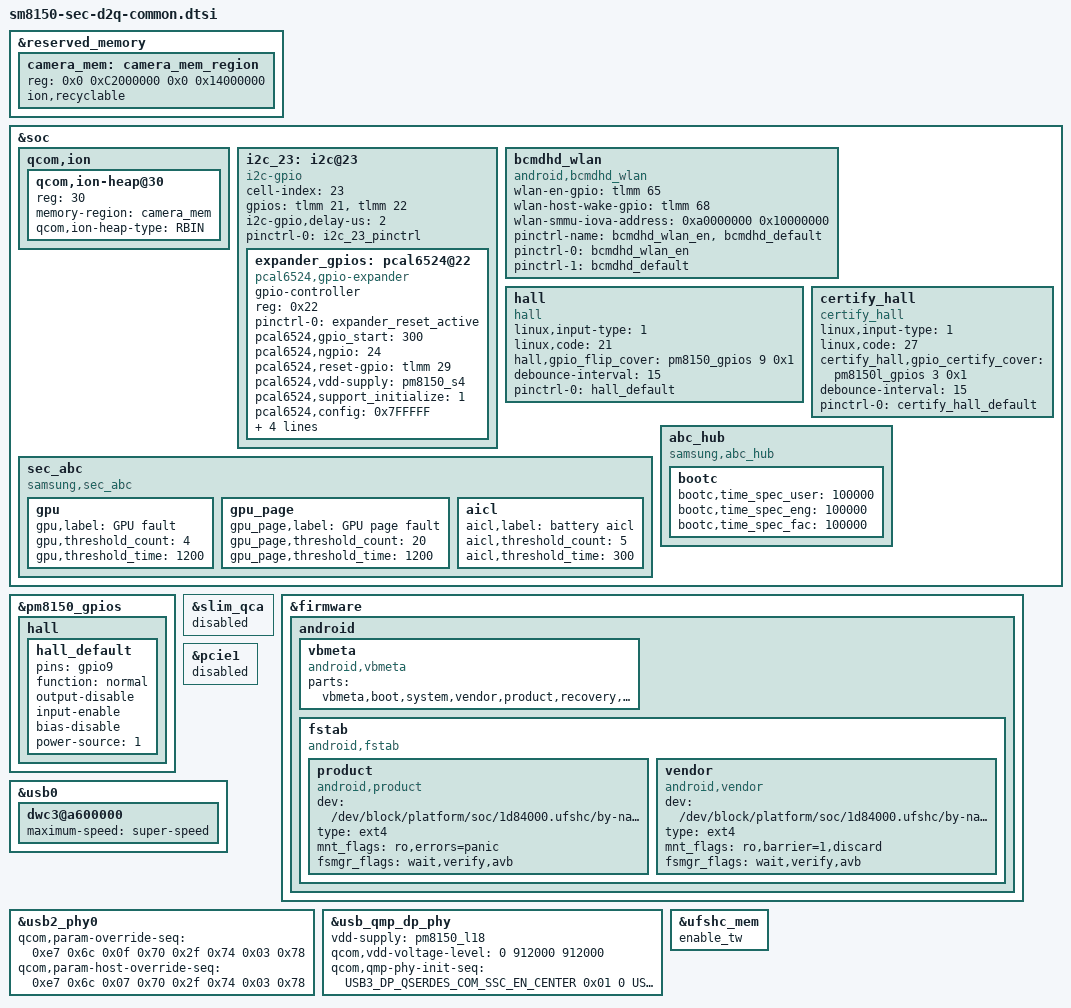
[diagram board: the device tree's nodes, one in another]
/* Copyright (c) 2016-2017, The Linux Foundation. All rights reserved.
 *
 * This program is free software; you can redistribute it and/or modify
 * it under the terms of the GNU General Public License version 2 and
 * only version 2 as published by the Free Software Foundation.
 *
 * This program is distributed in the hope that it will be useful,
 * but WITHOUT ANY WARRANTY; without even the implied warranty of
 * MERCHANTABILITY or FITNESS FOR A PARTICULAR PURPOSE.  See the
 * GNU General Public License for more details.
 */

#include "sm8150-sec-davinciq-audio.dtsi"
#include "sm8150-sec-d2xq-mst.dtsi"
#include <dt-bindings/phy/qcom,sm8150-qmp-usb3.h>
#include "sm8150-sec-d2q-input-common.dtsi"

&reserved_memory {
	camera_mem: camera_mem_region {
		reg = <0x0 0xC2000000 0x0 0x14000000>;
		ion,recyclable;
	};
};

&soc {
	qcom,ion {
		qcom,ion-heap@30 { /* CAMERA HEAP  */
			reg = <30>;
			memory-region = <&camera_mem>;
			qcom,ion-heap-type = "RBIN";
		};
	};
};

&pm8150_gpios {
	hall {
		hall_default: hall_default {
			pins = "gpio9";
			function = "normal";
			output-disable;
			input-enable;
			bias-disable;
			power-source = <1>;
		};
	};
};

&soc {
	i2c_23: i2c@23 {
		status = "ok";

		cell-index = <23>;
		compatible = "i2c-gpio";
		gpios = <&tlmm 21 0	/* EXPANDER_I2C_SDA_1P8 */
			 &tlmm 22 0	/* EXPANDER_I2C_SCL_1P8 */
		>;
		i2c-gpio,delay-us = <2>;
		#address-cells = <1>;
		#size-cells = <0>;

		pinctrl-names = "default";
		pinctrl-0 = <&i2c_23_pinctrl>;

		expander_gpios: pcal6524@22 {
			compatible = "pcal6524,gpio-expander";
			gpio-controller;
			#gpio-cells = <2>;
			reg = <0x22>;
			pinctrl-names = "expander_reset_setting";
			pinctrl-0 = <&expander_reset_active>;
			pcal6524,gpio_start = <300>;
			pcal6524,ngpio = <24>;
			pcal6524,reset-gpio = <&tlmm 29 0>;
			pcal6524,vdd-supply = <&pm8150_s4>;
			pcal6524,support_initialize = <1>;
			/* config, 24 ~ 0, 1bit configure[1:input, 0:output]*/
			pcal6524,config = <0x7FFFFF>;    /* P2[01111111] P1[11111111] P0[11111111] */
			/* data_out, 24 ~ 0, 1bit configure[1:high, 0:low]*/
			pcal6524,data_out = <0x000000>;  /* P2[00000000] P1[00000000] P0[00000000] */
			/* pull_reg, 8 ~ 0, 2bit configure[00:no_pull, 01:pull_down, 10:pull_up, 11:not used] */
			pcal6524,pull_reg_p0 = <0x0000>; /* 00 00 00 00 / 00 00 00 00 */
			pcal6524,pull_reg_p1 = <0x0000>; /* 00 00 00 00 / 00 00 00 00 */
			pcal6524,pull_reg_p2 = <0x0000>; /* 00 00 00 00 / 00 00 00 00 */
		};
	};

       bcmdhd_wlan {
		 compatible = "android,bcmdhd_wlan";
		 wlan-en-gpio = <&tlmm 65 0>;
		 wlan-host-wake-gpio = <&tlmm 68 0>;
		 wlan-smmu-iova-address = <0xa0000000 0x10000000>;
		 pinctrl-name = "bcmdhd_wlan_en","bcmdhd_default";
		 pinctrl-0 = <&bcmdhd_wlan_en>;
		 pinctrl-1 = <&bcmdhd_default>;
		 status = "ok";
	};

        hall {
                status = "okay";
                compatible = "hall";
                linux,input-type = <1>;
                linux,code = <21>;
                hall,gpio_flip_cover = <&pm8150_gpios 9 0x1>;
                debounce-interval = <15>;
		pinctrl-names = "default";
	        pinctrl-0 = <&hall_default>;
        };

        certify_hall {
                compatible = "certify_hall";
                linux,input-type = <1>;
                linux,code = <27>;
                certify_hall,gpio_certify_cover = <&pm8150l_gpios 3 0x1>;
                debounce-interval = <15>;
		pinctrl-names = "default";
	        pinctrl-0 = <&certify_hall_default>;
        };


	sec_abc {
		compatible = "samsung,sec_abc";
		status = "okay";

		gpu {
			gpu,label="GPU fault";
			gpu,threshold_count=<4>;
			gpu,threshold_time=<1200>;
		};
		gpu_page {
			gpu_page,label="GPU page fault";
			gpu_page,threshold_count=<20>;
			gpu_page,threshold_time=<1200>;
		};
		aicl {
			aicl,label="battery aicl";
			aicl,threshold_count=<5>;
			aicl,threshold_time=<300>;
		};
	};

	abc_hub {
		compatible = "samsung,abc_hub";
		status = "okay";

		bootc {
			bootc,time_spec_user = <100000>; /* user binary user build */
			bootc,time_spec_eng = <100000>; /* user binary eng build */
			bootc,time_spec_fac = <100000>; /* factory binary */
		};

	};
};

&slim_qca {
	status = "disabled";
};

&firmware {
	android {
		vbmeta {
			compatible = "android,vbmeta";
			parts = "vbmeta,boot,system,vendor,product,recovery,dtbo,abl,xbl,tz,hyp";
		};
		fstab {
            compatible = "android,fstab";
			product {
				compatible = "android,product";
				/* dev = "/dev/block/bootdevice/by-name/product"; */
				dev = "/dev/block/platform/soc/1d84000.ufshc/by-name/product";
				type = "ext4";
				mnt_flags = "ro,errors=panic";
				fsmgr_flags = "wait,verify,avb";
			};
			vendor {
				compatible = "android,vendor";
				/*dev = "/dev/block/bootdevice/by-name/vendor";*/
				dev = "/dev/block/platform/soc/1d84000.ufshc/by-name/vendor";
				type = "ext4";
				mnt_flags = "ro,barrier=1,discard";
				fsmgr_flags = "wait,verify,avb";
			};
		};
	};
};

&pcie1{
	status = "disabled";
};

&usb0 {
	dwc3@a600000 {
		maximum-speed = "super-speed";
	};
};

&usb2_phy0 {
	qcom,param-override-seq =
		<0xe7 0x6c
		 0x0f 0x70
		 0x2f 0x74
		 0x03 0x78>;
	qcom,param-host-override-seq =
		<0xe7 0x6c
		 0x07 0x70
		 0x2f 0x74
		 0x03 0x78>;
};

&usb_qmp_dp_phy {
	vdd-supply = <&pm8150_l18>;
	qcom,vdd-voltage-level = <0 912000 912000>;
	qcom,qmp-phy-init-seq =
	    <USB3_DP_QSERDES_COM_SSC_EN_CENTER 0x01 0
	     USB3_DP_QSERDES_COM_SSC_PER1 0x31 0
	     USB3_DP_QSERDES_COM_SSC_PER2 0x01 0
	     USB3_DP_QSERDES_COM_SSC_STEP_SIZE1_MODE0 0xde 0
	     USB3_DP_QSERDES_COM_SSC_STEP_SIZE2_MODE0 0x07 0
	     USB3_DP_QSERDES_COM_SSC_STEP_SIZE1_MODE1 0xde 0
	     USB3_DP_QSERDES_COM_SSC_STEP_SIZE2_MODE1 0x07 0
	     USB3_DP_QSERDES_COM_SYSCLK_BUF_ENABLE 0x0a 0
	     USB3_DP_QSERDES_COM_CP_CTRL_MODE0 0x06 0
	     USB3_DP_QSERDES_COM_CP_CTRL_MODE1 0x06 0
	     USB3_DP_QSERDES_COM_PLL_RCTRL_MODE0 0x16 0
	     USB3_DP_QSERDES_COM_PLL_RCTRL_MODE1 0x16 0
	     USB3_DP_QSERDES_COM_PLL_CCTRL_MODE0 0x36 0
	     USB3_DP_QSERDES_COM_PLL_CCTRL_MODE1 0x36 0
	     USB3_DP_QSERDES_COM_SYSCLK_EN_SEL 0x1a 0
	     USB3_DP_QSERDES_COM_LOCK_CMP_EN 0x04 0
	     USB3_DP_QSERDES_COM_LOCK_CMP1_MODE0 0x14 0
	     USB3_DP_QSERDES_COM_LOCK_CMP2_MODE0 0x34 0
	     USB3_DP_QSERDES_COM_LOCK_CMP1_MODE1 0x34 0
	     USB3_DP_QSERDES_COM_LOCK_CMP2_MODE1 0x82 0
	     USB3_DP_QSERDES_COM_DEC_START_MODE0 0x82 0
	     USB3_DP_QSERDES_COM_DEC_START_MODE1 0x82 0
	     USB3_DP_QSERDES_COM_DIV_FRAC_START1_MODE0 0xab 0
	     USB3_DP_QSERDES_COM_DIV_FRAC_START2_MODE0 0xea 0
	     USB3_DP_QSERDES_COM_DIV_FRAC_START3_MODE0 0x02 0
	     USB3_DP_QSERDES_COM_DIV_FRAC_START1_MODE1 0xab 0
	     USB3_DP_QSERDES_COM_DIV_FRAC_START2_MODE1 0xea 0
	     USB3_DP_QSERDES_COM_DIV_FRAC_START3_MODE1 0x02 0
	     USB3_DP_QSERDES_COM_VCO_TUNE1_MODE0 0x24 0
	     USB3_DP_QSERDES_COM_VCO_TUNE1_MODE1 0x24 0
	     USB3_DP_QSERDES_COM_VCO_TUNE2_MODE1 0x02 0
	     USB3_DP_QSERDES_COM_HSCLK_SEL 0x01 0
	     USB3_DP_QSERDES_COM_CORECLK_DIV_MODE1 0x08 0
	     USB3_DP_QSERDES_COM_SVS_MODE_CLK_SEL 0x2 0
	     USB3_DP_QSERDES_COM_BIN_VCOCAL_CMP_CODE1_MODE0 0xca 0
	     USB3_DP_QSERDES_COM_BIN_VCOCAL_CMP_CODE2_MODE0 0x1e 0
	     USB3_DP_QSERDES_COM_BIN_VCOCAL_CMP_CODE1_MODE1 0xca 0
	     USB3_DP_QSERDES_COM_BIN_VCOCAL_CMP_CODE2_MODE1 0x1e 0
	     USB3_DP_QSERDES_COM_BIN_VCOCAL_HSCLK_SEL 0x11 0
	     USB3_DP_QSERDES_COM_VCO_TUNE_MAP 0x02 0
	     USB3_DP_QSERDES_COM_CMN_IPTRIM 0x20 0
	     USB3_DP_QSERDES_TXA_LANE_MODE_1 0xd5 0
	     USB3_DP_QSERDES_TXA_RCV_DETECT_LVL_2 0x12 0
	     USB3_DP_QSERDES_TXA_RES_CODE_LANE_TX 0x00 0
	     USB3_DP_QSERDES_TXA_RES_CODE_LANE_RX 0x00 0
	     USB3_DP_QSERDES_TXA_RES_CODE_LANE_OFFSET_TX 0x16 0
	     USB3_DP_QSERDES_TXA_RES_CODE_LANE_OFFSET_RX 0x05 0
	     USB3_DP_QSERDES_TXA_PI_QEC_CTRL 0x20 0
	     USB3_DP_QSERDES_TXA_TX_DRV_LVL 0x3a 0
	     USB3_DP_QSERDES_RXA_UCDR_SO_GAIN 0x04 0
	     USB3_DP_QSERDES_RXA_UCDR_FASTLOCK_FO_GAIN 0x2f 0
	     USB3_DP_QSERDES_RXA_UCDR_SO_SATURATION_AND_ENABLE 0x7f 0
	     USB3_DP_QSERDES_RXA_UCDR_FASTLOCK_COUNT_LOW 0xff 0
	     USB3_DP_QSERDES_RXA_UCDR_FASTLOCK_COUNT_HIGH 0x0f 0
	     USB3_DP_QSERDES_RXA_UCDR_PI_CONTROLS 0x99 0
	     USB3_DP_QSERDES_RXA_UCDR_SB2_THRESH1 0x04 0
	     USB3_DP_QSERDES_RXA_UCDR_SB2_THRESH2 0x08 0
	     USB3_DP_QSERDES_RXA_UCDR_SB2_GAIN1 0x05 0
	     USB3_DP_QSERDES_RXA_UCDR_SB2_GAIN2 0x05 0
	     USB3_DP_QSERDES_RXA_AUX_DATA_TCOARSE_TFINE 0xa0 0
	     USB3_DP_QSERDES_RXA_VGA_CAL_CNTRL1 0x54 0
	     USB3_DP_QSERDES_RXA_VGA_CAL_CNTRL2 0x0e 0
	     USB3_DP_QSERDES_RXA_GM_CAL 0x1f 0
	     USB3_DP_QSERDES_RXA_RX_EQU_ADAPTOR_CNTRL2 0x0f 0
	     USB3_DP_QSERDES_RXA_RX_EQU_ADAPTOR_CNTRL3 0x4a 0
	     USB3_DP_QSERDES_RXA_RX_EQU_ADAPTOR_CNTRL4 0x0a 0
	     USB3_DP_QSERDES_RXA_RX_IDAC_TSETTLE_LOW 0xc0 0
	     USB3_DP_QSERDES_RXA_RX_IDAC_TSETTLE_HIGH 0x00 0
	     USB3_DP_QSERDES_RXA_RX_EQ_OFFSET_ADAPTOR_CNTRL1 0x77 0
	     USB3_DP_QSERDES_RXA_RX_OFFSET_ADAPTOR_CNTRL2 0x80 0
	     USB3_DP_QSERDES_RXA_SIGDET_CNTRL 0x04 0
	     USB3_DP_QSERDES_RXA_SIGDET_DEGLITCH_CNTRL 0x0e 0
	     USB3_DP_QSERDES_RXA_RX_MODE_00_LOW 0xbf 0
	     USB3_DP_QSERDES_RXA_RX_MODE_00_HIGH 0xbf 0
	     USB3_DP_QSERDES_RXA_RX_MODE_00_HIGH2 0x3f 0
	     USB3_DP_QSERDES_RXA_RX_MODE_00_HIGH3 0x7f 0
	     USB3_DP_QSERDES_RXA_RX_MODE_00_HIGH4 0x94 0
	     USB3_DP_QSERDES_RXA_RX_MODE_01_LOW 0xdc 0
	     USB3_DP_QSERDES_RXA_RX_MODE_01_HIGH 0xdc 0
	     USB3_DP_QSERDES_RXA_RX_MODE_01_HIGH2 0x5c 0
	     USB3_DP_QSERDES_RXA_RX_MODE_01_HIGH3 0x0b 0
	     USB3_DP_QSERDES_RXA_RX_MODE_01_HIGH4 0xb6 0
	     USB3_DP_QSERDES_RXA_DFE_EN_TIMER 0x04 0
	     USB3_DP_QSERDES_RXA_DFE_CTLE_POST_CAL_OFFSET 0x38 0
	     USB3_DP_QSERDES_RXA_DCC_CTRL1 0xc 0
	     USB3_DP_QSERDES_RXA_VTH_CODE 0x10 0
	     USB3_DP_QSERDES_TXB_LANE_MODE_1 0xd5 0
	     USB3_DP_QSERDES_TXB_RCV_DETECT_LVL_2 0x12 0
	     USB3_DP_QSERDES_TXB_RES_CODE_LANE_TX 0x00 0
	     USB3_DP_QSERDES_TXB_RES_CODE_LANE_RX 0x00 0
	     USB3_DP_QSERDES_TXB_RES_CODE_LANE_OFFSET_TX 0x16 0
	     USB3_DP_QSERDES_TXB_RES_CODE_LANE_OFFSET_RX 0x05 0
	     USB3_DP_QSERDES_TXB_PI_QEC_CTRL 0x20 0
	     USB3_DP_QSERDES_TXB_TX_DRV_LVL 0x3a 0
	     USB3_DP_QSERDES_RXB_UCDR_SO_GAIN 0x04 0
	     USB3_DP_QSERDES_RXB_UCDR_FASTLOCK_FO_GAIN 0x2f 0
	     USB3_DP_QSERDES_RXB_UCDR_SO_SATURATION_AND_ENABLE 0x7f 0
	     USB3_DP_QSERDES_RXB_UCDR_FASTLOCK_COUNT_LOW 0xff 0
	     USB3_DP_QSERDES_RXB_UCDR_FASTLOCK_COUNT_HIGH 0x0f 0
	     USB3_DP_QSERDES_RXB_UCDR_PI_CONTROLS 0x99 0
	     USB3_DP_QSERDES_RXB_UCDR_SB2_THRESH1 0x04 0
	     USB3_DP_QSERDES_RXB_UCDR_SB2_THRESH2 0x08 0
	     USB3_DP_QSERDES_RXB_UCDR_SB2_GAIN1 0x05 0
	     USB3_DP_QSERDES_RXB_UCDR_SB2_GAIN2 0x05 0
	     USB3_DP_QSERDES_RXB_AUX_DATA_TCOARSE_TFINE 0xa0 0
	     USB3_DP_QSERDES_RXB_VGA_CAL_CNTRL1 0x54 0
	     USB3_DP_QSERDES_RXB_VGA_CAL_CNTRL2 0x0e 0
	     USB3_DP_QSERDES_RXB_GM_CAL 0x1f 0
	     USB3_DP_QSERDES_RXB_RX_EQU_ADAPTOR_CNTRL2 0x0f 0
	     USB3_DP_QSERDES_RXB_RX_EQU_ADAPTOR_CNTRL3 0x4a 0
	     USB3_DP_QSERDES_RXB_RX_EQU_ADAPTOR_CNTRL4 0x0a 0
	     USB3_DP_QSERDES_RXB_RX_IDAC_TSETTLE_LOW 0xc0 0
	     USB3_DP_QSERDES_RXB_RX_IDAC_TSETTLE_HIGH 0x00 0
	     USB3_DP_QSERDES_RXB_RX_EQ_OFFSET_ADAPTOR_CNTRL1 0x77 0
	     USB3_DP_QSERDES_RXB_RX_OFFSET_ADAPTOR_CNTRL2 0x80 0
	     USB3_DP_QSERDES_RXB_SIGDET_CNTRL 0x04 0
	     USB3_DP_QSERDES_RXB_SIGDET_DEGLITCH_CNTRL 0x0e 0
	     USB3_DP_QSERDES_RXB_RX_MODE_00_LOW 0xbf 0
	     USB3_DP_QSERDES_RXB_RX_MODE_00_HIGH 0xbf 0
	     USB3_DP_QSERDES_RXB_RX_MODE_00_HIGH2 0x3f 0
	     USB3_DP_QSERDES_RXB_RX_MODE_00_HIGH3 0x7f 0
	     USB3_DP_QSERDES_RXB_RX_MODE_00_HIGH4 0x94 0
	     USB3_DP_QSERDES_RXB_RX_MODE_01_LOW 0xdc 0
	     USB3_DP_QSERDES_RXB_RX_MODE_01_HIGH 0xdc 0
	     USB3_DP_QSERDES_RXB_RX_MODE_01_HIGH2 0x5c 0
	     USB3_DP_QSERDES_RXB_RX_MODE_01_HIGH3 0x0b 0
	     USB3_DP_QSERDES_RXB_RX_MODE_01_HIGH4 0xb6 0
	     USB3_DP_QSERDES_RXB_DFE_EN_TIMER 0x04 0
	     USB3_DP_QSERDES_RXB_DFE_CTLE_POST_CAL_OFFSET 0x38 0
	     USB3_DP_QSERDES_RXB_DCC_CTRL1 0xc 0
	     USB3_DP_QSERDES_RXB_VTH_CODE 0x10 0
	     USB3_DP_PCS_LOCK_DETECT_CONFIG1 0xd0 0
	     USB3_DP_PCS_LOCK_DETECT_CONFIG2 0x17 0
	     USB3_DP_PCS_LOCK_DETECT_CONFIG3 0x20 0
	     USB3_DP_PCS_RX_SIGDET_LVL 0xaa 0
	     USB3_DP_PCS_ALIGN_DETECT_CONFIG1 0x88 0
	     USB3_DP_PCS_ALIGN_DETECT_CONFIG2 0x13 0
	     USB3_DP_PCS_EQ_CONFIG1 0x0d 0
	     USB3_DP_PCS_EQ_CONFIG5 0x50 0
	     USB3_DP_PCS_USB3_LFPS_DET_HIGH_COUNT_VAL 0xf8 0
	     USB3_DP_PCS_USB3_RXEQTRAINING_DFE_TIME_S2 0x07 0
	     0xffffffff 0xffffffff 0x00>;
};

&ufshc_mem {
	enable_tw;
};
